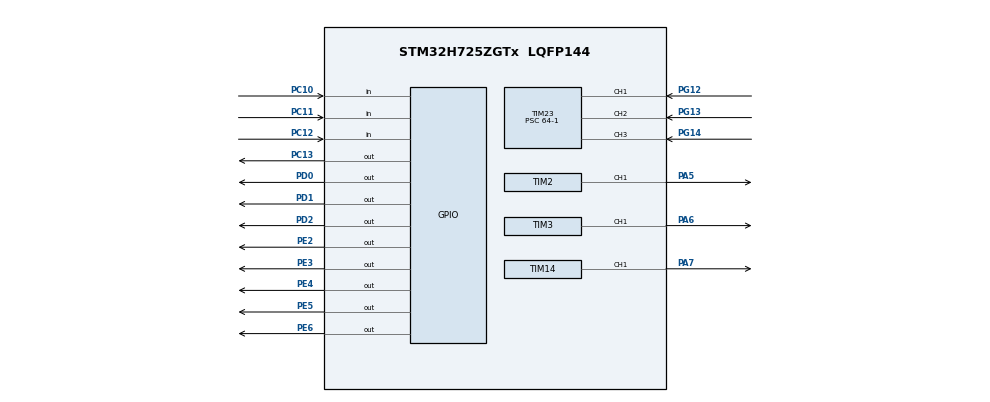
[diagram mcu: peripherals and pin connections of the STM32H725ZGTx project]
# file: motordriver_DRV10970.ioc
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Mcu.Family=STM32H7
Mcu.Name=STM32H725ZGTx
Mcu.Package=LQFP144
NVIC.PriorityGroup=NVIC_PRIORITYGROUP_4
PA5.Signal=S_TIM2_CH1_ETR
PA6.Signal=S_TIM3_CH1
PA7.Signal=S_TIM14_CH1
PC10.Signal=GPIO_Input
PC11.Signal=GPIO_Input
PC12.Signal=GPIO_Input
PC13.Signal=GPIO_Output
PD0.Signal=GPIO_Output
PD1.Signal=GPIO_Output
PD2.Signal=GPIO_Output
PE2.Signal=GPIO_Output
PE3.Signal=GPIO_Output
PE4.Signal=GPIO_Output
PE5.Signal=GPIO_Output
PE6.Signal=GPIO_Output
PG12.Mode=Input_Capture1_from_TI1
PG12.Signal=TIM23_CH1
PG13.Signal=S_TIM23_CH2
PG14.Signal=S_TIM23_CH3
PH0-OSC_IN.Mode=HSE-External-Oscillator
PH0-OSC_IN.Signal=RCC_OSC_IN
PH1-OSC_OUT.Mode=HSE-External-Oscillator
PH1-OSC_OUT.Signal=RCC_OSC_OUT
ProjectManager.HeapSize=0x200
ProjectManager.StackSize=0x400
ProjectManager.TargetToolchain=STM32CubeIDE
RCC.ADCFreq_Value=129000000
RCC.APB1Freq_Value=32000000
RCC.APB2Freq_Value=32000000
RCC.APB3Freq_Value=32000000
RCC.APB4Freq_Value=32000000
RCC.CortexFreq_Value=64000000
RCC.D1PPRE=RCC_APB3_DIV2
RCC.D2PPRE1=RCC_APB1_DIV2
RCC.D2PPRE2=RCC_APB2_DIV2
RCC.D3PPRE=RCC_APB4_DIV2
RCC.DIVM1=2
RCC.DIVN1=22
RCC.DIVP1=1
RCC.HCLKFreq_Value=64000000
RCC.PLLFRACN=0
RCC.SYSCLKFreq_VALUE=64000000
RCC.USBFreq_Value=352000000
SH.S_TIM14_CH1.0=TIM14_CH1,PWM Generation1 CH1
SH.S_TIM23_CH2.0=TIM23_CH2,Input_Capture2_from_TI2
SH.S_TIM23_CH3.0=TIM23_CH3,Input_Capture3_from_TI3
SH.S_TIM2_CH1_ETR.0=TIM2_CH1,PWM Generation1 CH1
SH.S_TIM3_CH1.0=TIM3_CH1,PWM Generation1 CH1
TIM14.Channel=TIM_CHANNEL_1
TIM14.Period=100-1
TIM14.Prescaler=64-1
TIM2.Channel-PWM\ Generation1\ CH1=TIM_CHANNEL_1
TIM2.Period=100-1
TIM2.Prescaler=64-1
TIM23.Channel-Input_Capture1_from_TI1=TIM_CHANNEL_1
TIM23.Channel-Input_Capture2_from_TI2=TIM_CHANNEL_2
TIM23.Channel-Input_Capture3_from_TI3=TIM_CHANNEL_3
TIM23.ICPolarity_CH1=TIM_INPUTCHANNELPOLARITY_BOTHEDGE
TIM23.Prescaler=64-1
TIM3.Channel-PWM\ Generation1\ CH1=TIM_CHANNEL_1
TIM3.Period=100-1
TIM3.Prescaler=64-1
VP_TIM14_VS_ClockSourceINT.Mode=Enable_Timer
VP_TIM23_VS_ClockSourceINT.Mode=Internal
VP_TIM2_VS_ClockSourceINT.Mode=Internal
VP_TIM3_VS_ClockSourceINT.Mode=Internal
board=custom

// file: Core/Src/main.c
/* USER CODE BEGIN Header */
/**
  ******************************************************************************
  * @file           : main.c
  * @brief          : Main program body
  ******************************************************************************
  * @attention
  *
  * Copyright (c) 2024 STMicroelectronics.
  * All rights reserved.
  *
  * This software is licensed under terms that can be found in the LICENSE file
  * in the root directory of this software component.
  * If no LICENSE file comes with this software, it is provided AS-IS.
  *
  ******************************************************************************
  */
/* USER CODE END Header */
#include "main.h"

/* USER CODE BEGIN Includes */
#include "motordriver.h"
/* USER CODE END Includes */

TIM_HandleTypeDef htim2;
TIM_HandleTypeDef htim3;
TIM_HandleTypeDef htim14;
TIM_HandleTypeDef htim23;

/* USER CODE BEGIN PV */
//following variables for testing purposes only
double *d_dutyx,*d_dutyy,*d_dutyz,*f_dutyx,*f_dutyy,*f_dutyz;

/* USER CODE END PV */

void SystemClock_Config(void);
static void MX_GPIO_Init(void);
static void MX_TIM2_Init(void);
static void MX_TIM3_Init(void);
static void MX_TIM14_Init(void);
static void MX_TIM23_Init(void);

int main(void)
{

  /* MCU Configuration--------------------------------------------------------*/

  /* Reset of all peripherals, Initializes the Flash interface and the Systick. */
  HAL_Init();

  /* Configure the system clock */
  SystemClock_Config();

  /* Initialize all configured peripherals */
  MX_GPIO_Init();  //motor initalize function will be called from here refer the MX_GPIO_Init function
  MX_TIM2_Init();
  MX_TIM3_Init();
  MX_TIM14_Init();
  MX_TIM23_Init();
  /* USER CODE BEGIN 2 */
  transfer(&htim2,&htim3,&htim14,&htim23,d_dutyx,d_dutyy,d_dutyz,f_dutyx,f_dutyy,f_dutyz);

  set_desired_motorx(50,1);
  set_desired_motory(25,0);
  set_desired_motory(75,1);
  HAL_Delay(20000);//check duty values during these 20s

  set_desired_motorx(55,1);
  set_desired_motory(20,0);
  set_desired_motory(90,0);
  HAL_Delay(20000);//check duty values during these 20s

  /* USER CODE END 2 */

  /* Infinite loop */
  while (1)
  {

  }
}

void SystemClock_Config(void)
{
  RCC_OscInitTypeDef RCC_OscInitStruct = {0};
  RCC_ClkInitTypeDef RCC_ClkInitStruct = {0};

  /** Supply configuration update enable
  */
  HAL_PWREx_ConfigSupply(PWR_DIRECT_SMPS_SUPPLY);

  /** Configure the main internal regulator output voltage
  */
  __HAL_PWR_VOLTAGESCALING_CONFIG(PWR_REGULATOR_VOLTAGE_SCALE3);

  while(!__HAL_PWR_GET_FLAG(PWR_FLAG_VOSRDY)) {}

  /** Initializes the RCC Oscillators according to the specified parameters
  * in the RCC_OscInitTypeDef structure.
  */
  RCC_OscInitStruct.OscillatorType = RCC_OSCILLATORTYPE_HSI;
  RCC_OscInitStruct.HSIState = RCC_HSI_DIV1;
  RCC_OscInitStruct.HSICalibrationValue = 64;
  RCC_OscInitStruct.PLL.PLLState = RCC_PLL_NONE;
  if (HAL_RCC_OscConfig(&RCC_OscInitStruct) != HAL_OK)
  {
    Error_Handler();
  }

  /** Initializes the CPU, AHB and APB buses clocks
  */
  RCC_ClkInitStruct.ClockType = RCC_CLOCKTYPE_HCLK|RCC_CLOCKTYPE_SYSCLK
                              |RCC_CLOCKTYPE_PCLK1|RCC_CLOCKTYPE_PCLK2
                              |RCC_CLOCKTYPE_D3PCLK1|RCC_CLOCKTYPE_D1PCLK1;
  RCC_ClkInitStruct.SYSCLKSource = RCC_SYSCLKSOURCE_HSI;
  RCC_ClkInitStruct.SYSCLKDivider = RCC_SYSCLK_DIV1;
  RCC_ClkInitStruct.AHBCLKDivider = RCC_HCLK_DIV1;
  RCC_ClkInitStruct.APB3CLKDivider = RCC_APB3_DIV2;
  RCC_ClkInitStruct.APB1CLKDivider = RCC_APB1_DIV2;
  RCC_ClkInitStruct.APB2CLKDivider = RCC_APB2_DIV2;
  RCC_ClkInitStruct.APB4CLKDivider = RCC_APB4_DIV2;

  if (HAL_RCC_ClockConfig(&RCC_ClkInitStruct, FLASH_LATENCY_1) != HAL_OK)
  {
    Error_Handler();
  }
}

static void MX_TIM2_Init(void)
{

  TIM_ClockConfigTypeDef sClockSourceConfig = {0};
  TIM_MasterConfigTypeDef sMasterConfig = {0};
  TIM_OC_InitTypeDef sConfigOC = {0};

  htim2.Instance = TIM2;
  htim2.Init.Prescaler = 64-1;
  htim2.Init.CounterMode = TIM_COUNTERMODE_UP;
  htim2.Init.Period = 100-1;
  htim2.Init.ClockDivision = TIM_CLOCKDIVISION_DIV1;
  htim2.Init.AutoReloadPreload = TIM_AUTORELOAD_PRELOAD_DISABLE;
  if (HAL_TIM_Base_Init(&htim2) != HAL_OK)
  {
    Error_Handler();
  }
  sClockSourceConfig.ClockSource = TIM_CLOCKSOURCE_INTERNAL;
  if (HAL_TIM_ConfigClockSource(&htim2, &sClockSourceConfig) != HAL_OK)
  {
    Error_Handler();
  }
  if (HAL_TIM_PWM_Init(&htim2) != HAL_OK)
  {
    Error_Handler();
  }
  sMasterConfig.MasterOutputTrigger = TIM_TRGO_RESET;
  sMasterConfig.MasterSlaveMode = TIM_MASTERSLAVEMODE_DISABLE;
  if (HAL_TIMEx_MasterConfigSynchronization(&htim2, &sMasterConfig) != HAL_OK)
  {
    Error_Handler();
  }
  sConfigOC.OCMode = TIM_OCMODE_PWM1;
  sConfigOC.Pulse = 0;
  sConfigOC.OCPolarity = TIM_OCPOLARITY_HIGH;
  sConfigOC.OCFastMode = TIM_OCFAST_DISABLE;
  if (HAL_TIM_PWM_ConfigChannel(&htim2, &sConfigOC, TIM_CHANNEL_1) != HAL_OK)
  {
    Error_Handler();
  }
  HAL_TIM_MspPostInit(&htim2);

}

static void MX_TIM3_Init(void)
{

  TIM_ClockConfigTypeDef sClockSourceConfig = {0};
  TIM_MasterConfigTypeDef sMasterConfig = {0};
  TIM_OC_InitTypeDef sConfigOC = {0};

  htim3.Instance = TIM3;
  htim3.Init.Prescaler = 64-1;
  htim3.Init.CounterMode = TIM_COUNTERMODE_UP;
  htim3.Init.Period = 100-1;
  htim3.Init.ClockDivision = TIM_CLOCKDIVISION_DIV1;
  htim3.Init.AutoReloadPreload = TIM_AUTORELOAD_PRELOAD_DISABLE;
  if (HAL_TIM_Base_Init(&htim3) != HAL_OK)
  {
    Error_Handler();
  }
  sClockSourceConfig.ClockSource = TIM_CLOCKSOURCE_INTERNAL;
  if (HAL_TIM_ConfigClockSource(&htim3, &sClockSourceConfig) != HAL_OK)
  {
    Error_Handler();
  }
  if (HAL_TIM_PWM_Init(&htim3) != HAL_OK)
  {
    Error_Handler();
  }
  sMasterConfig.MasterOutputTrigger = TIM_TRGO_RESET;
  sMasterConfig.MasterSlaveMode = TIM_MASTERSLAVEMODE_DISABLE;
  if (HAL_TIMEx_MasterConfigSynchronization(&htim3, &sMasterConfig) != HAL_OK)
  {
    Error_Handler();
  }
  sConfigOC.OCMode = TIM_OCMODE_PWM1;
  sConfigOC.Pulse = 0;
  sConfigOC.OCPolarity = TIM_OCPOLARITY_HIGH;
  sConfigOC.OCFastMode = TIM_OCFAST_DISABLE;
  if (HAL_TIM_PWM_ConfigChannel(&htim3, &sConfigOC, TIM_CHANNEL_1) != HAL_OK)
  {
    Error_Handler();
  }
  HAL_TIM_MspPostInit(&htim3);

}

static void MX_TIM14_Init(void)
{

  TIM_OC_InitTypeDef sConfigOC = {0};

  htim14.Instance = TIM14;
  htim14.Init.Prescaler = 64-1;
  htim14.Init.CounterMode = TIM_COUNTERMODE_UP;
  htim14.Init.Period = 100-1;
  htim14.Init.ClockDivision = TIM_CLOCKDIVISION_DIV1;
  htim14.Init.AutoReloadPreload = TIM_AUTORELOAD_PRELOAD_DISABLE;
  if (HAL_TIM_Base_Init(&htim14) != HAL_OK)
  {
    Error_Handler();
  }
  if (HAL_TIM_PWM_Init(&htim14) != HAL_OK)
  {
    Error_Handler();
  }
  sConfigOC.OCMode = TIM_OCMODE_PWM1;
  sConfigOC.Pulse = 0;
  sConfigOC.OCPolarity = TIM_OCPOLARITY_HIGH;
  sConfigOC.OCFastMode = TIM_OCFAST_DISABLE;
  if (HAL_TIM_PWM_ConfigChannel(&htim14, &sConfigOC, TIM_CHANNEL_1) != HAL_OK)
  {
    Error_Handler();
  }
  HAL_TIM_MspPostInit(&htim14);

}

static void MX_TIM23_Init(void)
{

  TIM_ClockConfigTypeDef sClockSourceConfig = {0};
  TIM_MasterConfigTypeDef sMasterConfig = {0};
  TIM_IC_InitTypeDef sConfigIC = {0};

  htim23.Instance = TIM23;
  htim23.Init.Prescaler = 64-1;
  htim23.Init.CounterMode = TIM_COUNTERMODE_UP;
  htim23.Init.Period = 4294967295;
  htim23.Init.ClockDivision = TIM_CLOCKDIVISION_DIV1;
  htim23.Init.AutoReloadPreload = TIM_AUTORELOAD_PRELOAD_DISABLE;
  if (HAL_TIM_Base_Init(&htim23) != HAL_OK)
  {
    Error_Handler();
  }
  sClockSourceConfig.ClockSource = TIM_CLOCKSOURCE_INTERNAL;
  if (HAL_TIM_ConfigClockSource(&htim23, &sClockSourceConfig) != HAL_OK)
  {
    Error_Handler();
  }
  if (HAL_TIM_IC_Init(&htim23) != HAL_OK)
  {
    Error_Handler();
  }
  sMasterConfig.MasterOutputTrigger = TIM_TRGO_RESET;
  sMasterConfig.MasterSlaveMode = TIM_MASTERSLAVEMODE_DISABLE;
  if (HAL_TIMEx_MasterConfigSynchronization(&htim23, &sMasterConfig) != HAL_OK)
  {
    Error_Handler();
  }
  sConfigIC.ICPolarity = TIM_INPUTCHANNELPOLARITY_BOTHEDGE;
  sConfigIC.ICSelection = TIM_ICSELECTION_DIRECTTI;
  sConfigIC.ICPrescaler = TIM_ICPSC_DIV1;
  sConfigIC.ICFilter = 0;
  if (HAL_TIM_IC_ConfigChannel(&htim23, &sConfigIC, TIM_CHANNEL_1) != HAL_OK)
  {
    Error_Handler();
  }
  sConfigIC.ICPolarity = TIM_INPUTCHANNELPOLARITY_RISING;
  if (HAL_TIM_IC_ConfigChannel(&htim23, &sConfigIC, TIM_CHANNEL_2) != HAL_OK)
  {
    Error_Handler();
  }
  if (HAL_TIM_IC_ConfigChannel(&htim23, &sConfigIC, TIM_CHANNEL_3) != HAL_OK)
  {
    Error_Handler();
  }

}

static void MX_GPIO_Init(void)
{
  GPIO_InitTypeDef GPIO_InitStruct = {0};

  /* GPIO Ports Clock Enable */
  __HAL_RCC_GPIOE_CLK_ENABLE();
  __HAL_RCC_GPIOC_CLK_ENABLE();
  __HAL_RCC_GPIOH_CLK_ENABLE();
  __HAL_RCC_GPIOA_CLK_ENABLE();
  __HAL_RCC_GPIOD_CLK_ENABLE();
  __HAL_RCC_GPIOG_CLK_ENABLE();

  /*Configure GPIO pin Output Level */
  HAL_GPIO_WritePin(GPIOE, GPIO_PIN_2|GPIO_PIN_3|GPIO_PIN_4|GPIO_PIN_5
                          |GPIO_PIN_6, GPIO_PIN_RESET);

  /*Configure GPIO pin Output Level */
  HAL_GPIO_WritePin(GPIOC, GPIO_PIN_13, GPIO_PIN_RESET);

  /*Configure GPIO pin Output Level */
  HAL_GPIO_WritePin(GPIOD, GPIO_PIN_0|GPIO_PIN_1|GPIO_PIN_2, GPIO_PIN_RESET);

  /*Configure GPIO pins : PE2 PE3 PE4 PE5
                           PE6 */
  GPIO_InitStruct.Pin = GPIO_PIN_2|GPIO_PIN_3|GPIO_PIN_4|GPIO_PIN_5
                          |GPIO_PIN_6;
  GPIO_InitStruct.Mode = GPIO_MODE_OUTPUT_PP;
  GPIO_InitStruct.Pull = GPIO_NOPULL;
  GPIO_InitStruct.Speed = GPIO_SPEED_FREQ_LOW;
  HAL_GPIO_Init(GPIOE, &GPIO_InitStruct);

  /*Configure GPIO pin : PC13 */
  GPIO_InitStruct.Pin = GPIO_PIN_13;
  GPIO_InitStruct.Mode = GPIO_MODE_OUTPUT_PP;
  GPIO_InitStruct.Pull = GPIO_NOPULL;
  GPIO_InitStruct.Speed = GPIO_SPEED_FREQ_LOW;
  HAL_GPIO_Init(GPIOC, &GPIO_InitStruct);

  /*Configure GPIO pins : PC10 PC11 PC12 */
  GPIO_InitStruct.Pin = GPIO_PIN_10|GPIO_PIN_11|GPIO_PIN_12;
  GPIO_InitStruct.Mode = GPIO_MODE_INPUT;
  GPIO_InitStruct.Pull = GPIO_NOPULL;
  HAL_GPIO_Init(GPIOC, &GPIO_InitStruct);

  /*Configure GPIO pins : PD0 PD1 PD2 */
  GPIO_InitStruct.Pin = GPIO_PIN_0|GPIO_PIN_1|GPIO_PIN_2;
  GPIO_InitStruct.Mode = GPIO_MODE_OUTPUT_PP;
  GPIO_InitStruct.Pull = GPIO_NOPULL;
  GPIO_InitStruct.Speed = GPIO_SPEED_FREQ_LOW;
  HAL_GPIO_Init(GPIOD, &GPIO_InitStruct);

/* USER CODE BEGIN MX_GPIO_Init_2 */
  motor_initialize(&GPIO_InitStruct);
/* USER CODE END MX_GPIO_Init_2 */
}

void Error_Handler(void)
{
  __disable_irq();
  while (1)
  {
  }
}
